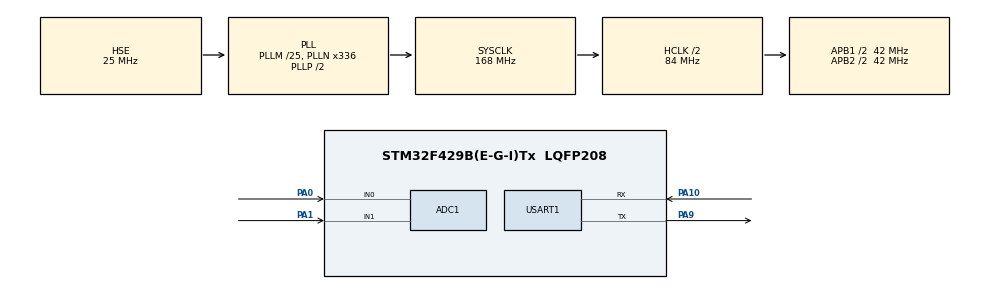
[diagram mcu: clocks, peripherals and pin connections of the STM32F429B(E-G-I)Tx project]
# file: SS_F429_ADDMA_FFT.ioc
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ADC1.Channel-1\#ChannelRegularConversion=ADC_CHANNEL_0
ADC1.Channel-3\#ChannelRegularConversion=ADC_CHANNEL_1
ADC1.ClockPrescaler=ADC_CLOCK_SYNC_PCLK_DIV2
ADC1.ContinuousConvMode=ENABLE
ADC1.DMAContinuousRequests=ENABLE
ADC1.DiscontinuousConvMode=DISABLE
ADC1.ExternalTrigConv=ADC_SOFTWARE_START
ADC1.NbrOfConversion=2
ADC1.NbrOfConversionFlag=1
ADC1.Rank-1\#ChannelRegularConversion=1
ADC1.Rank-3\#ChannelRegularConversion=2
ADC1.SamplingTime-1\#ChannelRegularConversion=ADC_SAMPLETIME_3CYCLES
ADC1.SamplingTime-3\#ChannelRegularConversion=ADC_SAMPLETIME_3CYCLES
ADC1.ScanConvMode=ENABLE
ADC1.master=1
Dma.ADC1.0.Direction=DMA_PERIPH_TO_MEMORY
Dma.ADC1.0.FIFOMode=DMA_FIFOMODE_DISABLE
Dma.ADC1.0.Instance=DMA2_Stream0
Dma.ADC1.0.MemDataAlignment=DMA_MDATAALIGN_WORD
Dma.ADC1.0.MemInc=DMA_MINC_ENABLE
Dma.ADC1.0.Mode=DMA_NORMAL
Dma.ADC1.0.PeriphDataAlignment=DMA_PDATAALIGN_WORD
Dma.ADC1.0.PeriphInc=DMA_PINC_DISABLE
Dma.ADC1.0.Priority=DMA_PRIORITY_LOW
Dma.Request0=ADC1
Mcu.Family=STM32F4
Mcu.Name=STM32F429B(E-G-I)Tx
Mcu.Package=LQFP208
NVIC.DMA2_Stream0_IRQn=true\:0\:0\:false\:false\:true\:false\:true
NVIC.PriorityGroup=NVIC_PRIORITYGROUP_4
PA0/WKUP.Signal=ADCx_IN0
PA1.Signal=ADCx_IN1
PA10.Mode=Asynchronous
PA10.Signal=USART1_RX
PA9.Mode=Asynchronous
PA9.Signal=USART1_TX
PH0/OSC_IN.Mode=HSE-External-Oscillator
PH0/OSC_IN.Signal=RCC_OSC_IN
PH1/OSC_OUT.Mode=HSE-External-Oscillator
PH1/OSC_OUT.Signal=RCC_OSC_OUT
ProjectManager.HeapSize=0x200
ProjectManager.StackSize=0x400
ProjectManager.TargetToolchain=MDK-ARM V5.27
RCC.48MHZClocksFreq_Value=84000000
RCC.AHBCLKDivider=RCC_SYSCLK_DIV2
RCC.AHBFreq_Value=84000000
RCC.APB1CLKDivider=RCC_HCLK_DIV2
RCC.APB1Freq_Value=42000000
RCC.APB1TimFreq_Value=84000000
RCC.APB2CLKDivider=RCC_HCLK_DIV2
RCC.APB2Freq_Value=42000000
RCC.APB2TimFreq_Value=84000000
RCC.CortexFreq_Value=84000000
RCC.HCLKFreq_Value=84000000
RCC.HSE_VALUE=25000000
RCC.HSI_VALUE=16000000
RCC.LSE_VALUE=32768
RCC.PLLM=25
RCC.PLLN=336
RCC.PLLSourceVirtual=RCC_PLLSOURCE_HSE
RCC.SYSCLKFreq_VALUE=168000000
RCC.SYSCLKSource=RCC_SYSCLKSOURCE_PLLCLK
RCC.VCOOutputFreq_Value=336000000
SH.ADCx_IN0.0=ADC1_IN0,IN0
SH.ADCx_IN1.0=ADC1_IN1,IN1
USART1.VirtualMode=VM_ASYNC
board=custom

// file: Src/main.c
/* USER CODE BEGIN Header */
/**
  ******************************************************************************
  * @file           : main.c
  * @brief          : Main program body
  ******************************************************************************
  * @attention
  *
  * <h2><center>&copy; Copyright (c) 2020 STMicroelectronics.
  * All rights reserved.</center></h2>
  *
  * This software component is licensed by ST under BSD 3-Clause license,
  * the "License"; You may not use this file except in compliance with the
  * License. You may obtain a copy of the License at:
  *                        opensource.org/licenses/BSD-3-Clause
  *
  ******************************************************************************
  */
/* USER CODE END Header */

#include "main.h"
#include "adc.h"
#include "dma.h"
#include "usart.h"
#include "gpio.h"

/* USER CODE BEGIN Includes */
#include "MF_FFT.h"
#include "MF_ADC_DMA.h"
#include "stdio.h"
#include "math.h"
/* USER CODE END Includes */

void SystemClock_Config(void);

int main(void)
{
  /* USER CODE BEGIN 1 */
	uint32_t receiveBuff[20] = {0} ;
	int i ;
  /* USER CODE END 1 */

  /* MCU Configuration--------------------------------------------------------*/

  /* Reset of all peripherals, Initializes the Flash interface and the Systick. */
  HAL_Init();

  /* Configure the system clock */
  SystemClock_Config();

  /* Initialize all configured peripherals */
  MX_GPIO_Init();
  MX_DMA_Init();
  MX_ADC1_Init();
  MX_USART1_UART_Init();

  /* Infinite loop */
  /* USER CODE BEGIN WHILE */
  while (1)
  {
		HAL_ADC_Start_DMA(&hadc1,(uint32_t *)&receiveBuff,20);
		HAL_Delay(1000);
		HAL_ADC_Stop_DMA(&hadc1);
		for(i = 0 ; i < 10 ; i+=2){
			printf("Singular:0x%8x,%.3f mv\r\n",receiveBuff[i],1000*receiveBuff[i]*MF_Frequency);
			printf("Dual    :0x%8x,%.3f mV\r\n",receiveBuff[i+1],1000*receiveBuff[i+1]*MF_Frequency);
		}
		printf("\r\n\r\n");
		HAL_Delay(1000);
    /* USER CODE END WHILE */

  }
}

void SystemClock_Config(void)
{
  RCC_OscInitTypeDef RCC_OscInitStruct = {0};
  RCC_ClkInitTypeDef RCC_ClkInitStruct = {0};

  /** Configure the main internal regulator output voltage
  */
  __HAL_RCC_PWR_CLK_ENABLE();
  __HAL_PWR_VOLTAGESCALING_CONFIG(PWR_REGULATOR_VOLTAGE_SCALE3);
  /** Initializes the CPU, AHB and APB busses clocks
  */
  RCC_OscInitStruct.OscillatorType = RCC_OSCILLATORTYPE_HSE;
  RCC_OscInitStruct.HSEState = RCC_HSE_ON;
  RCC_OscInitStruct.PLL.PLLState = RCC_PLL_ON;
  RCC_OscInitStruct.PLL.PLLSource = RCC_PLLSOURCE_HSE;
  RCC_OscInitStruct.PLL.PLLM = 25;
  RCC_OscInitStruct.PLL.PLLN = 336;
  RCC_OscInitStruct.PLL.PLLP = RCC_PLLP_DIV2;
  RCC_OscInitStruct.PLL.PLLQ = 4;
  if (HAL_RCC_OscConfig(&RCC_OscInitStruct) != HAL_OK)
  {
    Error_Handler();
  }
  /** Initializes the CPU, AHB and APB busses clocks
  */
  RCC_ClkInitStruct.ClockType = RCC_CLOCKTYPE_HCLK|RCC_CLOCKTYPE_SYSCLK
                              |RCC_CLOCKTYPE_PCLK1|RCC_CLOCKTYPE_PCLK2;
  RCC_ClkInitStruct.SYSCLKSource = RCC_SYSCLKSOURCE_PLLCLK;
  RCC_ClkInitStruct.AHBCLKDivider = RCC_SYSCLK_DIV2;
  RCC_ClkInitStruct.APB1CLKDivider = RCC_HCLK_DIV2;
  RCC_ClkInitStruct.APB2CLKDivider = RCC_HCLK_DIV2;

  if (HAL_RCC_ClockConfig(&RCC_ClkInitStruct, FLASH_LATENCY_2) != HAL_OK)
  {
    Error_Handler();
  }
}

void Error_Handler(void)
{
}

/************************ (C) COPYRIGHT STMicroelectronics *****END OF FILE****/
